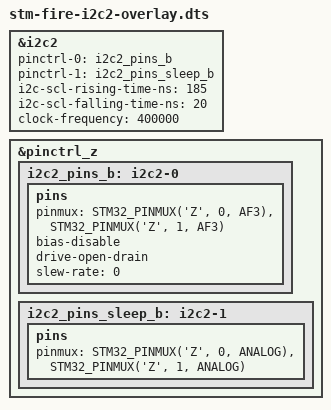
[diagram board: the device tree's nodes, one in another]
// SPDX-License-Identifier: (GPL-2.0+ OR BSD-3-Clause)
/*
 * Copyright (C) STMicroelectronics 2018 - All Rights Reserved
 * Author: Alexandre Torgue <alexandre.torgue@st.com>.
 */

/dts-v1/;
/plugin/;
//#include "../stm32mp157c.dtsi"
#include <dt-bindings/pinctrl/stm32-pinfunc.h>
#include <dt-bindings/input/input.h>
#include <dt-bindings/mfd/st,stpmic1.h>
#include <dt-bindings/gpio/gpio.h>

/{
	fragment@0{
		target=<&i2c2>;
		__overlay__{
			pinctrl-names = "default", "sleep";
			pinctrl-0 = <&i2c2_pins_b>;
			pinctrl-1 = <&i2c2_pins_sleep_b>;
			i2c-scl-rising-time-ns = <185>;
			i2c-scl-falling-time-ns = <20>;
			clock-frequency = <400000>;
			status = "okay";	
			/delete-property/dmas;
			/delete-property/dma-names;				
		};
	};
	fragment@1{
		target=<&pinctrl_z>;
		__overlay__{		
			i2c2_pins_b: i2c2-0 {
				pins {
					pinmux = <STM32_PINMUX('Z', 0, AF3)>, /* I2C2_SCL */
							<STM32_PINMUX('Z', 1, AF3)>; /* I2C2_SDA */
					bias-disable;
					drive-open-drain;
					slew-rate = <0>;
				};
			};

			i2c2_pins_sleep_b: i2c2-1 {
				pins {
					pinmux = <STM32_PINMUX('Z', 0, ANALOG)>, /* I2C2_SCL */
							<STM32_PINMUX('Z', 1, ANALOG)>; /* I2C2_SDA */
				};
			};

		};
	};
};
